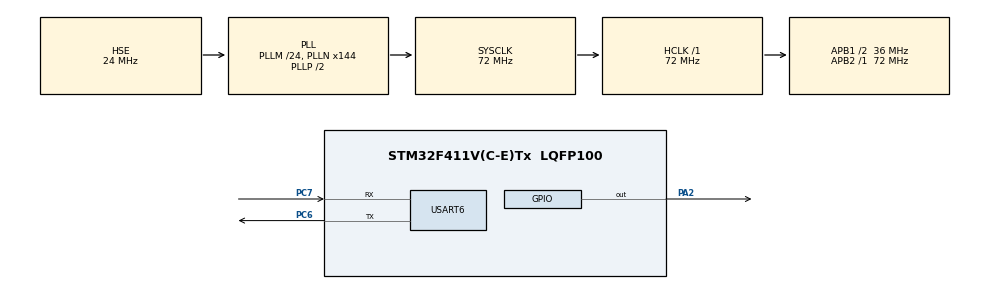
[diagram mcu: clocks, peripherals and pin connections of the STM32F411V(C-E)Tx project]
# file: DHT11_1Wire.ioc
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Mcu.Family=STM32F4
Mcu.Name=STM32F411V(C-E)Tx
Mcu.Package=LQFP100
NVIC.PriorityGroup=NVIC_PRIORITYGROUP_4
NVIC.TIM2_IRQn=true\:0\:0\:false\:false\:true\:true\:true\:true
PA13.Mode=Serial_Wire
PA13.Signal=SYS_JTMS-SWDIO
PA14.Mode=Serial_Wire
PA14.Signal=SYS_JTCK-SWCLK
PA2.Signal=GPIO_Output
PC6.Mode=Asynchronous
PC6.Signal=USART6_TX
PC7.Mode=Asynchronous
PC7.Signal=USART6_RX
PH0\ -\ OSC_IN.Mode=HSE-External-Oscillator
PH0\ -\ OSC_IN.Signal=RCC_OSC_IN
PH1\ -\ OSC_OUT.Mode=HSE-External-Oscillator
PH1\ -\ OSC_OUT.Signal=RCC_OSC_OUT
ProjectManager.HeapSize=0x200
ProjectManager.StackSize=0x400
ProjectManager.TargetToolchain=STM32CubeIDE
RCC.48MHZClocksFreq_Value=36000000
RCC.AHBFreq_Value=72000000
RCC.APB1CLKDivider=RCC_HCLK_DIV2
RCC.APB1Freq_Value=36000000
RCC.APB1TimFreq_Value=72000000
RCC.APB2Freq_Value=72000000
RCC.APB2TimFreq_Value=72000000
RCC.CortexFreq_Value=72000000
RCC.HCLKFreq_Value=72000000
RCC.HSE_VALUE=24000000
RCC.HSI_VALUE=16000000
RCC.LSE_VALUE=32768
RCC.PLLM=24
RCC.PLLN=144
RCC.PLLSourceVirtual=RCC_PLLSOURCE_HSE
RCC.SYSCLKFreq_VALUE=72000000
RCC.SYSCLKSource=RCC_SYSCLKSOURCE_PLLCLK
RCC.VCOOutputFreq_Value=144000000
TIM2.Period=0xffff-1
TIM2.Prescaler=71
USART6.VirtualMode=VM_ASYNC
VP_TIM2_VS_ClockSourceINT.Mode=Internal
board=custom

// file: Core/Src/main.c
/* USER CODE BEGIN Header */
/**
  ******************************************************************************
  * @file           : main.c
  * @brief          : Main program body
  ******************************************************************************
  * @attention
  *
  * Copyright (c) 2022 STMicroelectronics.
  * All rights reserved.
  *
  * This software is licensed under terms that can be found in the LICENSE file
  * in the root directory of this software component.
  * If no LICENSE file comes with this software, it is provided AS-IS.
  *
  ******************************************************************************
  */
/* USER CODE END Header */
#include "main.h"

/* USER CODE BEGIN Includes */
#include "stdio.h"
#include "string.h"
/* USER CODE END Includes */

 TIM_HandleTypeDef htim2;

UART_HandleTypeDef huart6;

void SystemClock_Config(void);
static void MX_GPIO_Init(void);
static void MX_USART6_UART_Init(void);
static void MX_TIM2_Init(void);

/* USER CODE BEGIN 0 */
#define DHT11_PORT GPIOA
#define DHT11_PIN GPIO_PIN_2
uint8_t RHI, RHD, TCI, TCD, SUM;
uint32_t pMillis, cMillis;
float tCelsius = 0;
float tFahrenheit = 0;
float RH = 0;

void microDelay (uint16_t delay)
{
  __HAL_TIM_SET_COUNTER(&htim2, 0);
  uint32_t time = __HAL_TIM_GET_COUNTER(&htim2);
  while (__HAL_TIM_GET_COUNTER(&htim2) < delay)
  {
	  time = __HAL_TIM_GET_COUNTER(&htim2);
  }
}

uint8_t DHT11_Start (void)
{
  uint8_t Response = 0;
  GPIO_InitTypeDef GPIO_InitStructPrivate = {0};
  GPIO_InitStructPrivate.Pin = DHT11_PIN;
  GPIO_InitStructPrivate.Mode = GPIO_MODE_OUTPUT_PP;
  GPIO_InitStructPrivate.Speed = GPIO_SPEED_FREQ_LOW;
  GPIO_InitStructPrivate.Pull = GPIO_NOPULL;
  HAL_GPIO_Init(DHT11_PORT, &GPIO_InitStructPrivate); // set the pin as output
  HAL_GPIO_WritePin (DHT11_PORT, DHT11_PIN, 0);   // pull the pin low
  HAL_Delay(20);   // wait for 20ms
  HAL_GPIO_WritePin (DHT11_PORT, DHT11_PIN, 1);   // pull the pin high
  microDelay (30);   // wait for 30us
  GPIO_InitStructPrivate.Mode = GPIO_MODE_INPUT;
  GPIO_InitStructPrivate.Pull = GPIO_PULLUP;
  HAL_GPIO_Init(DHT11_PORT, &GPIO_InitStructPrivate); // set the pin as input
  microDelay (40);
  if (!(HAL_GPIO_ReadPin (DHT11_PORT, DHT11_PIN)))
  {
    microDelay (80);
    if ((HAL_GPIO_ReadPin (DHT11_PORT, DHT11_PIN))) Response = 1;
  }
  pMillis = HAL_GetTick();
  cMillis = HAL_GetTick();
  while ((HAL_GPIO_ReadPin (DHT11_PORT, DHT11_PIN)) && pMillis + 2 > cMillis)
  {
    cMillis = HAL_GetTick();
  }
  return Response;
}

uint8_t DHT11_Read (void)
{
  uint8_t a,b;
  for (a=0;a<8;a++)
  {
    pMillis = HAL_GetTick();
    cMillis = HAL_GetTick();
    while (!(HAL_GPIO_ReadPin (DHT11_PORT, DHT11_PIN)) && pMillis + 2 > cMillis)
    {  // wait for the pin to go high
      cMillis = HAL_GetTick();
    }
    microDelay (40);   // wait for 40 us
    if (!(HAL_GPIO_ReadPin (DHT11_PORT, DHT11_PIN)))   // if the pin is low
      b&= ~(1<<(7-a));
    else
      b|= (1<<(7-a));
    pMillis = HAL_GetTick();
    cMillis = HAL_GetTick();
    while ((HAL_GPIO_ReadPin (DHT11_PORT, DHT11_PIN)) && pMillis + 2 > cMillis)
    {  // wait for the pin to go low
      cMillis = HAL_GetTick();
    }
  }
  return b;
}
/* USER CODE END 0 */

int main(void)
{

  /* MCU Configuration--------------------------------------------------------*/

  /* Reset of all peripherals, Initializes the Flash interface and the Systick. */
  HAL_Init();

  /* Configure the system clock */
  SystemClock_Config();

  /* Initialize all configured peripherals */
  MX_GPIO_Init();
  MX_USART6_UART_Init();
  MX_TIM2_Init();
  /* USER CODE BEGIN 2 */
  char tempBuffer[20] = { 0 };
  	char humiBuffer[20] = { 0 };
  /* USER CODE END 2 */

  /* Infinite loop */
  /* USER CODE BEGIN WHILE */
  while (1)
  {
		/********************** DHT11 *********************/
		    if(DHT11_Start())
		    {
		      RHI = DHT11_Read(); // Relative humidity integral
		      RHD = DHT11_Read(); // Relative humidity decimal
		      TCI = DHT11_Read(); // Celsius integral
		      TCD = DHT11_Read(); // Celsius decimal
		      SUM = DHT11_Read(); // Check sum
		      if (RHI + RHD + TCI + TCD == SUM)
		      {
		        // Can use RHI and TCI for any purposes if whole number only needed
		        tCelsius = (float)TCI + (float)(TCD/10.0);
		        tFahrenheit = tCelsius * 9/5 + 32;
		        RH = (float)RHI + (float)(RHD/10.0);
		        // Can use tCelsius, tFahrenheit and RH for any purposes
		      }

//				lcd_puts(0, 0, (int8_t*) "Humi: ");
//				sprintf(humiBuffer, "%.2f", RH);
//				lcd_puts(0, 8, (int8_t*) humiBuffer);
//				lcd_puts(1, 0, (int8_t*) "Temp: ");
//				sprintf(tempBuffer, "%.2f", tCelsius);
//				lcd_puts(1, 8, (int8_t*) tempBuffer);

			sprintf(humiBuffer, "Humi: %.2f \n", RH);
			HAL_UART_Transmit(&huart6, humiBuffer, 20, 1000);
			sprintf(tempBuffer, "Humi: %.2f \n\n", tCelsius);
			HAL_UART_Transmit(&huart6, tempBuffer, 20, 1000);
		    }
		    HAL_UART_Transmit(&huart6, "Long", 4, 1000);
		    HAL_Delay(500);
    /* USER CODE END WHILE */

  }
}

void SystemClock_Config(void)
{
  RCC_OscInitTypeDef RCC_OscInitStruct = {0};
  RCC_ClkInitTypeDef RCC_ClkInitStruct = {0};

  /** Configure the main internal regulator output voltage
  */
  __HAL_RCC_PWR_CLK_ENABLE();
  __HAL_PWR_VOLTAGESCALING_CONFIG(PWR_REGULATOR_VOLTAGE_SCALE1);

  /** Initializes the RCC Oscillators according to the specified parameters
  * in the RCC_OscInitTypeDef structure.
  */
  RCC_OscInitStruct.OscillatorType = RCC_OSCILLATORTYPE_HSE;
  RCC_OscInitStruct.HSEState = RCC_HSE_ON;
  RCC_OscInitStruct.PLL.PLLState = RCC_PLL_ON;
  RCC_OscInitStruct.PLL.PLLSource = RCC_PLLSOURCE_HSE;
  RCC_OscInitStruct.PLL.PLLM = 24;
  RCC_OscInitStruct.PLL.PLLN = 144;
  RCC_OscInitStruct.PLL.PLLP = RCC_PLLP_DIV2;
  RCC_OscInitStruct.PLL.PLLQ = 4;
  if (HAL_RCC_OscConfig(&RCC_OscInitStruct) != HAL_OK)
  {
    Error_Handler();
  }

  /** Initializes the CPU, AHB and APB buses clocks
  */
  RCC_ClkInitStruct.ClockType = RCC_CLOCKTYPE_HCLK|RCC_CLOCKTYPE_SYSCLK
                              |RCC_CLOCKTYPE_PCLK1|RCC_CLOCKTYPE_PCLK2;
  RCC_ClkInitStruct.SYSCLKSource = RCC_SYSCLKSOURCE_PLLCLK;
  RCC_ClkInitStruct.AHBCLKDivider = RCC_SYSCLK_DIV1;
  RCC_ClkInitStruct.APB1CLKDivider = RCC_HCLK_DIV2;
  RCC_ClkInitStruct.APB2CLKDivider = RCC_HCLK_DIV1;

  if (HAL_RCC_ClockConfig(&RCC_ClkInitStruct, FLASH_LATENCY_2) != HAL_OK)
  {
    Error_Handler();
  }
}

static void MX_TIM2_Init(void)
{

  TIM_ClockConfigTypeDef sClockSourceConfig = {0};
  TIM_MasterConfigTypeDef sMasterConfig = {0};

  htim2.Instance = TIM2;
  htim2.Init.Prescaler = 71;
  htim2.Init.CounterMode = TIM_COUNTERMODE_UP;
  htim2.Init.Period = 0xffff-1;
  htim2.Init.ClockDivision = TIM_CLOCKDIVISION_DIV1;
  htim2.Init.AutoReloadPreload = TIM_AUTORELOAD_PRELOAD_DISABLE;
  if (HAL_TIM_Base_Init(&htim2) != HAL_OK)
  {
    Error_Handler();
  }
  sClockSourceConfig.ClockSource = TIM_CLOCKSOURCE_INTERNAL;
  if (HAL_TIM_ConfigClockSource(&htim2, &sClockSourceConfig) != HAL_OK)
  {
    Error_Handler();
  }
  sMasterConfig.MasterOutputTrigger = TIM_TRGO_RESET;
  sMasterConfig.MasterSlaveMode = TIM_MASTERSLAVEMODE_DISABLE;
  if (HAL_TIMEx_MasterConfigSynchronization(&htim2, &sMasterConfig) != HAL_OK)
  {
    Error_Handler();
  }

}

static void MX_USART6_UART_Init(void)
{

  huart6.Instance = USART6;
  huart6.Init.BaudRate = 115200;
  huart6.Init.WordLength = UART_WORDLENGTH_8B;
  huart6.Init.StopBits = UART_STOPBITS_1;
  huart6.Init.Parity = UART_PARITY_NONE;
  huart6.Init.Mode = UART_MODE_TX_RX;
  huart6.Init.HwFlowCtl = UART_HWCONTROL_NONE;
  huart6.Init.OverSampling = UART_OVERSAMPLING_16;
  if (HAL_UART_Init(&huart6) != HAL_OK)
  {
    Error_Handler();
  }

}

static void MX_GPIO_Init(void)
{
  GPIO_InitTypeDef GPIO_InitStruct = {0};

  /* GPIO Ports Clock Enable */
  __HAL_RCC_GPIOH_CLK_ENABLE();
  __HAL_RCC_GPIOA_CLK_ENABLE();
  __HAL_RCC_GPIOC_CLK_ENABLE();

  /*Configure GPIO pin Output Level */
  HAL_GPIO_WritePin(GPIOA, GPIO_PIN_2, GPIO_PIN_RESET);

  /*Configure GPIO pin : PA2 */
  GPIO_InitStruct.Pin = GPIO_PIN_2;
  GPIO_InitStruct.Mode = GPIO_MODE_OUTPUT_PP;
  GPIO_InitStruct.Pull = GPIO_NOPULL;
  GPIO_InitStruct.Speed = GPIO_SPEED_FREQ_LOW;
  HAL_GPIO_Init(GPIOA, &GPIO_InitStruct);

}

void Error_Handler(void)
{
  __disable_irq();
  while (1)
  {
  }
}
